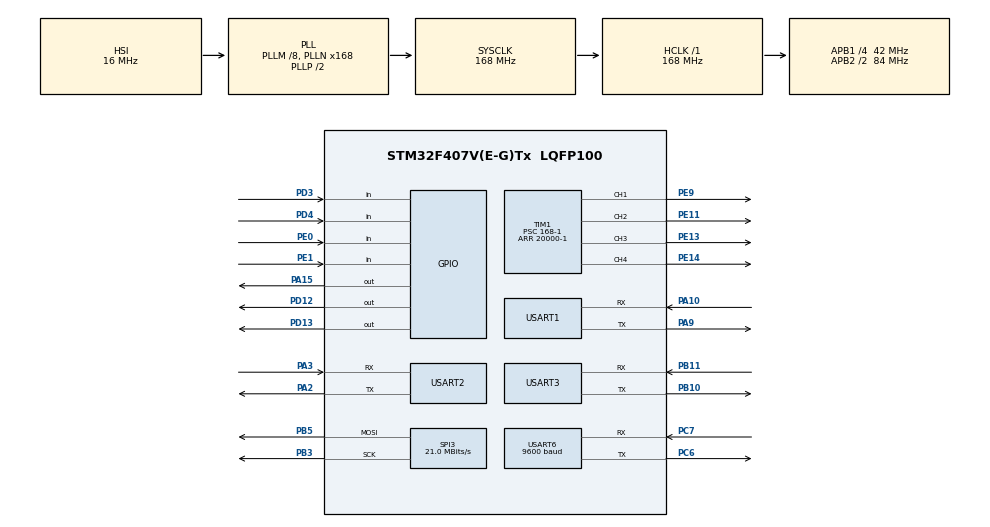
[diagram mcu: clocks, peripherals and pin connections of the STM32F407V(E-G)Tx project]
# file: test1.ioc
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Dma.Request0=USART3_RX
Dma.Request1=USART2_RX
Dma.Request2=USART2_TX
Dma.Request3=USART1_RX
Dma.Request4=USART1_TX
Dma.Request5=USART6_RX
Dma.Request6=USART6_TX
Dma.USART1_RX.3.Direction=DMA_PERIPH_TO_MEMORY
Dma.USART1_RX.3.FIFOMode=DMA_FIFOMODE_DISABLE
Dma.USART1_RX.3.Instance=DMA2_Stream2
Dma.USART1_RX.3.MemDataAlignment=DMA_MDATAALIGN_BYTE
Dma.USART1_RX.3.MemInc=DMA_MINC_ENABLE
Dma.USART1_RX.3.Mode=DMA_CIRCULAR
Dma.USART1_RX.3.PeriphDataAlignment=DMA_PDATAALIGN_BYTE
Dma.USART1_RX.3.PeriphInc=DMA_PINC_DISABLE
Dma.USART1_RX.3.Priority=DMA_PRIORITY_LOW
Dma.USART1_TX.4.Direction=DMA_MEMORY_TO_PERIPH
Dma.USART1_TX.4.FIFOMode=DMA_FIFOMODE_DISABLE
Dma.USART1_TX.4.Instance=DMA2_Stream7
Dma.USART1_TX.4.MemDataAlignment=DMA_MDATAALIGN_BYTE
Dma.USART1_TX.4.MemInc=DMA_MINC_ENABLE
Dma.USART1_TX.4.Mode=DMA_NORMAL
Dma.USART1_TX.4.PeriphDataAlignment=DMA_PDATAALIGN_BYTE
Dma.USART1_TX.4.PeriphInc=DMA_PINC_DISABLE
Dma.USART1_TX.4.Priority=DMA_PRIORITY_LOW
Dma.USART2_RX.1.Direction=DMA_PERIPH_TO_MEMORY
Dma.USART2_RX.1.FIFOMode=DMA_FIFOMODE_DISABLE
Dma.USART2_RX.1.Instance=DMA1_Stream5
Dma.USART2_RX.1.MemDataAlignment=DMA_MDATAALIGN_BYTE
Dma.USART2_RX.1.MemInc=DMA_MINC_ENABLE
Dma.USART2_RX.1.Mode=DMA_CIRCULAR
Dma.USART2_RX.1.PeriphDataAlignment=DMA_PDATAALIGN_BYTE
Dma.USART2_RX.1.PeriphInc=DMA_PINC_DISABLE
Dma.USART2_RX.1.Priority=DMA_PRIORITY_LOW
Dma.USART2_TX.2.Direction=DMA_MEMORY_TO_PERIPH
Dma.USART2_TX.2.FIFOMode=DMA_FIFOMODE_DISABLE
Dma.USART2_TX.2.Instance=DMA1_Stream6
Dma.USART2_TX.2.MemDataAlignment=DMA_MDATAALIGN_BYTE
Dma.USART2_TX.2.MemInc=DMA_MINC_ENABLE
Dma.USART2_TX.2.Mode=DMA_NORMAL
Dma.USART2_TX.2.PeriphDataAlignment=DMA_PDATAALIGN_BYTE
Dma.USART2_TX.2.PeriphInc=DMA_PINC_DISABLE
Dma.USART2_TX.2.Priority=DMA_PRIORITY_LOW
Dma.USART3_RX.0.Direction=DMA_PERIPH_TO_MEMORY
Dma.USART3_RX.0.FIFOMode=DMA_FIFOMODE_DISABLE
Dma.USART3_RX.0.Instance=DMA1_Stream1
Dma.USART3_RX.0.MemDataAlignment=DMA_MDATAALIGN_BYTE
Dma.USART3_RX.0.MemInc=DMA_MINC_ENABLE
Dma.USART3_RX.0.Mode=DMA_CIRCULAR
Dma.USART3_RX.0.PeriphDataAlignment=DMA_PDATAALIGN_BYTE
Dma.USART3_RX.0.PeriphInc=DMA_PINC_DISABLE
Dma.USART3_RX.0.Priority=DMA_PRIORITY_LOW
Dma.USART6_RX.5.Direction=DMA_PERIPH_TO_MEMORY
Dma.USART6_RX.5.FIFOMode=DMA_FIFOMODE_DISABLE
Dma.USART6_RX.5.Instance=DMA2_Stream1
Dma.USART6_RX.5.MemDataAlignment=DMA_MDATAALIGN_BYTE
Dma.USART6_RX.5.MemInc=DMA_MINC_ENABLE
Dma.USART6_RX.5.Mode=DMA_CIRCULAR
Dma.USART6_RX.5.PeriphDataAlignment=DMA_PDATAALIGN_BYTE
Dma.USART6_RX.5.PeriphInc=DMA_PINC_DISABLE
Dma.USART6_RX.5.Priority=DMA_PRIORITY_LOW
Dma.USART6_TX.6.Direction=DMA_MEMORY_TO_PERIPH
Dma.USART6_TX.6.FIFOMode=DMA_FIFOMODE_DISABLE
Dma.USART6_TX.6.Instance=DMA2_Stream6
Dma.USART6_TX.6.MemDataAlignment=DMA_MDATAALIGN_BYTE
Dma.USART6_TX.6.MemInc=DMA_MINC_ENABLE
Dma.USART6_TX.6.Mode=DMA_NORMAL
Dma.USART6_TX.6.PeriphDataAlignment=DMA_PDATAALIGN_BYTE
Dma.USART6_TX.6.PeriphInc=DMA_PINC_DISABLE
Dma.USART6_TX.6.Priority=DMA_PRIORITY_LOW
Mcu.Family=STM32F4
Mcu.Name=STM32F407V(E-G)Tx
Mcu.Package=LQFP100
NVIC.DMA1_Stream1_IRQn=true\:0\:0\:false\:false\:true\:false\:true\:true
NVIC.DMA1_Stream5_IRQn=true\:0\:0\:false\:false\:true\:false\:true\:true
NVIC.DMA1_Stream6_IRQn=true\:0\:0\:false\:false\:true\:false\:true\:true
NVIC.DMA2_Stream1_IRQn=true\:0\:0\:false\:false\:true\:false\:true\:true
NVIC.DMA2_Stream2_IRQn=true\:0\:0\:false\:false\:true\:false\:true\:true
NVIC.DMA2_Stream6_IRQn=true\:0\:0\:false\:false\:true\:false\:true\:true
NVIC.DMA2_Stream7_IRQn=true\:0\:0\:false\:false\:true\:false\:true\:true
NVIC.PriorityGroup=NVIC_PRIORITYGROUP_4
NVIC.USART1_IRQn=true\:0\:0\:false\:false\:true\:true\:true\:true
NVIC.USART2_IRQn=true\:0\:0\:false\:false\:true\:true\:true\:true
NVIC.USART3_IRQn=true\:0\:0\:false\:false\:true\:true\:true\:true
NVIC.USART6_IRQn=true\:0\:0\:false\:false\:true\:true\:true\:true
PA10.Mode=Asynchronous
PA10.Signal=USART1_RX
PA13.Mode=Serial_Wire
PA13.Signal=SYS_JTMS-SWDIO
PA14.Mode=Serial_Wire
PA14.Signal=SYS_JTCK-SWCLK
PA15.Signal=GPIO_Output
PA2.Mode=Asynchronous
PA2.Signal=USART2_TX
PA3.Mode=Asynchronous
PA3.Signal=USART2_RX
PA9.Mode=Asynchronous
PA9.Signal=USART1_TX
PB10.Mode=Asynchronous
PB10.Signal=USART3_TX
PB11.Mode=Asynchronous
PB11.Signal=USART3_RX
PB3.Mode=TX_Only_Simplex_Unidirect_Master
PB3.Signal=SPI3_SCK
PB5.Mode=TX_Only_Simplex_Unidirect_Master
PB5.Signal=SPI3_MOSI
PC6.Mode=Asynchronous
PC6.Signal=USART6_TX
PC7.Mode=Asynchronous
PC7.Signal=USART6_RX
PD12.Signal=GPIO_Output
PD13.Signal=GPIO_Output
PD3.GPIO_PuPd=GPIO_PULLDOWN
PD3.Signal=GPIO_Input
PD4.Signal=GPIO_Input
PE0.Signal=GPIO_Input
PE1.Signal=GPIO_Input
PE11.Signal=S_TIM1_CH2
PE13.Signal=S_TIM1_CH3
PE14.Signal=S_TIM1_CH4
PE9.Signal=S_TIM1_CH1
PH0-OSC_IN.Mode=HSE-External-Oscillator
PH0-OSC_IN.Signal=RCC_OSC_IN
PH1-OSC_OUT.Mode=HSE-External-Oscillator
PH1-OSC_OUT.Signal=RCC_OSC_OUT
ProjectManager.HeapSize=0x200
ProjectManager.StackSize=0x400
ProjectManager.TargetToolchain=MDK-ARM V5.32
RCC.48MHZClocksFreq_Value=84000000
RCC.AHBFreq_Value=168000000
RCC.APB1CLKDivider=RCC_HCLK_DIV4
RCC.APB1Freq_Value=42000000
RCC.APB1TimFreq_Value=84000000
RCC.APB2CLKDivider=RCC_HCLK_DIV2
RCC.APB2Freq_Value=84000000
RCC.APB2TimFreq_Value=168000000
RCC.CortexFreq_Value=168000000
RCC.HCLKFreq_Value=168000000
RCC.HSE_VALUE=25000000
RCC.HSI_VALUE=16000000
RCC.LSE_VALUE=32768
RCC.PLLM=8
RCC.PLLN=168
RCC.SYSCLKFreq_VALUE=168000000
RCC.SYSCLKSource=RCC_SYSCLKSOURCE_PLLCLK
RCC.VCOOutputFreq_Value=336000000
SH.S_TIM1_CH1.0=TIM1_CH1,PWM Generation1 CH1
SH.S_TIM1_CH2.0=TIM1_CH2,PWM Generation2 CH2
SH.S_TIM1_CH3.0=TIM1_CH3,PWM Generation3 CH3
SH.S_TIM1_CH4.0=TIM1_CH4,PWM Generation4 CH4
SPI3.CalculateBaudRate=21.0 MBits/s
SPI3.Direction=SPI_DIRECTION_2LINES
SPI3.Mode=SPI_MODE_MASTER
SPI3.VirtualType=VM_MASTER
TIM1.AutoReloadPreload=TIM_AUTORELOAD_PRELOAD_ENABLE
TIM1.Channel-PWM\ Generation1\ CH1=TIM_CHANNEL_1
TIM1.Channel-PWM\ Generation2\ CH2=TIM_CHANNEL_2
TIM1.Channel-PWM\ Generation3\ CH3=TIM_CHANNEL_3
TIM1.Channel-PWM\ Generation4\ CH4=TIM_CHANNEL_4
TIM1.OCPolarity_1=TIM_OCPOLARITY_HIGH
TIM1.OCPolarity_2=TIM_OCPOLARITY_HIGH
TIM1.OCPolarity_3=TIM_OCPOLARITY_HIGH
TIM1.OCPolarity_4=TIM_OCPOLARITY_HIGH
TIM1.Period=20000-1
TIM1.Prescaler=168-1
TIM1.Pulse-PWM\ Generation1\ CH1=2004
TIM1.Pulse-PWM\ Generation2\ CH2=889
TIM1.Pulse-PWM\ Generation3\ CH3=778
TIM1.Pulse-PWM\ Generation4\ CH4=1167
USART1.VirtualMode=VM_ASYNC
USART2.VirtualMode=VM_ASYNC
USART3.VirtualMode=VM_ASYNC
USART6.BaudRate=9600
USART6.VirtualMode=VM_ASYNC
VP_TIM1_VS_ClockSourceINT.Mode=Internal
board=custom

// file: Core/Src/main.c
/* USER CODE BEGIN Header */
/**
  ******************************************************************************
  * @file           : main.c
  * @brief          : Main program body
  ******************************************************************************
  * @attention
  *
  * Copyright (c) 2025 STMicroelectronics.
  * All rights reserved.
  *
  * This software is licensed under terms that can be found in the LICENSE file
  * in the root directory of this software component.
  * If no LICENSE file comes with this software, it is provided AS-IS.
  *
  ******************************************************************************
  */
/* USER CODE END Header */
#include "main.h"
#include "dma.h"
#include "spi.h"
#include "tim.h"
#include "usart.h"
#include "gpio.h"

/* USER CODE BEGIN Includes */
#include "headfile.h"
/* USER CODE END Includes */

void SystemClock_Config(void);

int main(void)
{

  /* MCU Configuration--------------------------------------------------------*/

  /* Reset of all peripherals, Initializes the Flash interface and the Systick. */
  HAL_Init();

  /* Configure the system clock */
  SystemClock_Config();

  /* Initialize all configured peripherals */
  MX_GPIO_Init();
  MX_DMA_Init();
  MX_USART1_UART_Init();
  MX_USART2_UART_Init();
  MX_USART3_UART_Init();
  MX_SPI3_Init();
  MX_USART6_UART_Init();
  MX_TIM1_Init();
  /* USER CODE BEGIN 2 */

  once_task();

  /* USER CODE END 2 */

  /* Infinite loop */
  while (1)
  {

    /* USER CODE BEGIN 3 */
    while_task();
  }
  /* USER CODE END 3 */
}

void SystemClock_Config(void)
{
  RCC_OscInitTypeDef RCC_OscInitStruct = {0};
  RCC_ClkInitTypeDef RCC_ClkInitStruct = {0};

  /** Configure the main internal regulator output voltage
  */
  __HAL_RCC_PWR_CLK_ENABLE();
  __HAL_PWR_VOLTAGESCALING_CONFIG(PWR_REGULATOR_VOLTAGE_SCALE1);

  /** Initializes the RCC Oscillators according to the specified parameters
  * in the RCC_OscInitTypeDef structure.
  */
  RCC_OscInitStruct.OscillatorType = RCC_OSCILLATORTYPE_HSI;
  RCC_OscInitStruct.HSIState = RCC_HSI_ON;
  RCC_OscInitStruct.HSICalibrationValue = RCC_HSICALIBRATION_DEFAULT;
  RCC_OscInitStruct.PLL.PLLState = RCC_PLL_ON;
  RCC_OscInitStruct.PLL.PLLSource = RCC_PLLSOURCE_HSI;
  RCC_OscInitStruct.PLL.PLLM = 8;
  RCC_OscInitStruct.PLL.PLLN = 168;
  RCC_OscInitStruct.PLL.PLLP = RCC_PLLP_DIV2;
  RCC_OscInitStruct.PLL.PLLQ = 4;
  if (HAL_RCC_OscConfig(&RCC_OscInitStruct) != HAL_OK)
  {
    Error_Handler();
  }

  /** Initializes the CPU, AHB and APB buses clocks
  */
  RCC_ClkInitStruct.ClockType = RCC_CLOCKTYPE_HCLK|RCC_CLOCKTYPE_SYSCLK
                              |RCC_CLOCKTYPE_PCLK1|RCC_CLOCKTYPE_PCLK2;
  RCC_ClkInitStruct.SYSCLKSource = RCC_SYSCLKSOURCE_PLLCLK;
  RCC_ClkInitStruct.AHBCLKDivider = RCC_SYSCLK_DIV1;
  RCC_ClkInitStruct.APB1CLKDivider = RCC_HCLK_DIV4;
  RCC_ClkInitStruct.APB2CLKDivider = RCC_HCLK_DIV2;

  if (HAL_RCC_ClockConfig(&RCC_ClkInitStruct, FLASH_LATENCY_5) != HAL_OK)
  {
    Error_Handler();
  }
}

void Error_Handler(void)
{
  __disable_irq();
  while (1)
  {
  }
}
